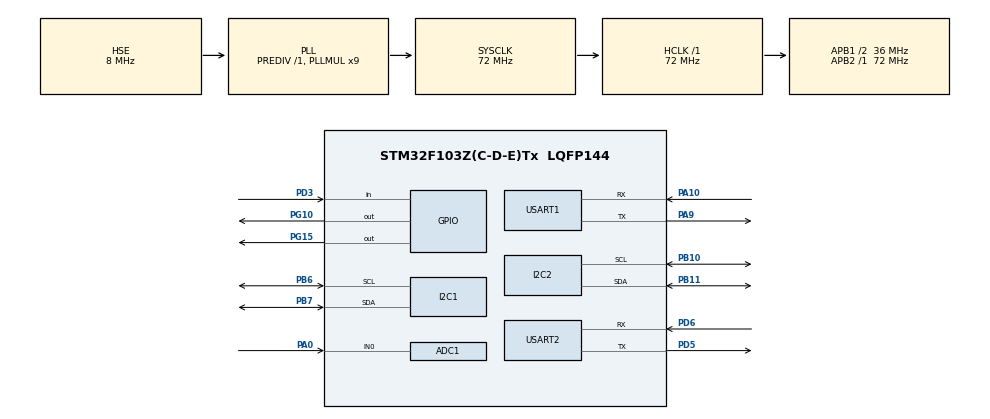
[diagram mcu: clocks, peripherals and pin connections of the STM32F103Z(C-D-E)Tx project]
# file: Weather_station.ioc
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ADC1.Channel-0\#ChannelRegularConversion=ADC_CHANNEL_0
ADC1.EnableInjectedConversion=ENABLE
ADC1.InjNumberOfConversion=1
ADC1.NbrOfConversion=1
ADC1.NbrOfConversionFlag=1
ADC1.Rank-0\#ChannelRegularConversion=1
ADC1.SamplingTime-0\#ChannelRegularConversion=ADC_SAMPLETIME_1CYCLE_5
ADC1.master=1
Mcu.Family=STM32F1
Mcu.Name=STM32F103Z(C-D-E)Tx
Mcu.Package=LQFP144
NVIC.PriorityGroup=NVIC_PRIORITYGROUP_4
NVIC.USART1_IRQn=true\:0\:0\:false\:false\:true\:true\:true\:true
OSC_IN.Mode=HSE-External-Oscillator
OSC_IN.Signal=RCC_OSC_IN
OSC_OUT.Mode=HSE-External-Oscillator
OSC_OUT.Signal=RCC_OSC_OUT
PA0-WKUP.Signal=ADCx_IN0
PA10.Mode=Asynchronous
PA10.Signal=USART1_RX
PA13.Mode=Serial_Wire
PA13.Signal=SYS_JTMS-SWDIO
PA14.Mode=Serial_Wire
PA14.Signal=SYS_JTCK-SWCLK
PA9.Mode=Asynchronous
PA9.Signal=USART1_TX
PB10.Mode=I2C
PB10.Signal=I2C2_SCL
PB11.Mode=I2C
PB11.Signal=I2C2_SDA
PB6.Mode=I2C
PB6.Signal=I2C1_SCL
PB7.Mode=I2C
PB7.Signal=I2C1_SDA
PC14-OSC32_IN.Mode=LSE-External-Oscillator
PC14-OSC32_IN.Signal=RCC_OSC32_IN
PC15-OSC32_OUT.Mode=LSE-External-Oscillator
PC15-OSC32_OUT.Signal=RCC_OSC32_OUT
PD3.Signal=GPIO_Input
PD5.Mode=Asynchronous
PD5.Signal=USART2_TX
PD6.Mode=Asynchronous
PD6.Signal=USART2_RX
PG10.GPIO_ModeDefaultOutputPP=GPIO_MODE_OUTPUT_PP
PG10.GPIO_PuPd=GPIO_PULLDOWN
PG10.PinState=GPIO_PIN_RESET
PG10.Signal=GPIO_Output
PG15.GPIO_PuPd=GPIO_PULLDOWN
PG15.Signal=GPIO_Output
ProjectManager.HeapSize=0x200
ProjectManager.StackSize=0x400
ProjectManager.TargetToolchain=Makefile
RCC.ADCPresc=RCC_ADCPCLK2_DIV6
RCC.AHBFreq_Value=72000000
RCC.APB1CLKDivider=RCC_HCLK_DIV2
RCC.APB1Freq_Value=36000000
RCC.APB1TimFreq_Value=72000000
RCC.APB2Freq_Value=72000000
RCC.APB2TimFreq_Value=72000000
RCC.HCLKFreq_Value=72000000
RCC.PLLMUL=RCC_PLL_MUL9
RCC.PLLSourceVirtual=RCC_PLLSOURCE_HSE
RCC.SYSCLKFreq_VALUE=72000000
RCC.SYSCLKSource=RCC_SYSCLKSOURCE_PLLCLK
RCC.USBFreq_Value=72000000
SH.ADCx_IN0.0=ADC1_IN0,IN0
TIM4.Period=20000-1
TIM4.Prescaler=7200-1
USART1.VirtualMode=VM_ASYNC
USART2.VirtualMode=VM_ASYNC
VP_TIM4_VS_ClockSourceINT.Mode=Internal
board=custom

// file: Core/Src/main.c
/* USER CODE BEGIN Header */
/**
  ******************************************************************************
  * @file           : main.c
  * @brief          : Main program body
  ******************************************************************************
  * @attention
  *
  * Copyright (c) 2026 STMicroelectronics.
  * All rights reserved.
  *
  * This software is licensed under terms that can be found in the LICENSE file
  * in the root directory of this software component.
  * If no LICENSE file comes with this software, it is provided AS-IS.
  *
  ******************************************************************************
  */
/* USER CODE END Header */
#include "main.h"
#include "adc.h"
#include "i2c.h"
#include "tim.h"
#include "usart.h"
#include "gpio.h"

/* USER CODE BEGIN Includes */
#include "app/app.h"
#include "test/test.h"
/* USER CODE END Includes */

void SystemClock_Config(void);

int main(void)
{

  /* MCU Configuration--------------------------------------------------------*/

  /* Reset of all peripherals, Initializes the Flash interface and the Systick. */
  HAL_Init();

  /* Configure the system clock */
  SystemClock_Config();

  /* Initialize all configured peripherals */
  MX_GPIO_Init();
  MX_USART1_UART_Init();
  MX_USART2_UART_Init();
  MX_ADC1_Init();
  MX_I2C1_Init();
  MX_I2C2_Init();
  MX_TIM4_Init();
  /* USER CODE BEGIN 2 */
  // app_init();
  test_hw_init();
  /* USER CODE END 2 */

  /* Infinite loop */
  while (1)
  {
    test_hw_loop();
  }
}

void SystemClock_Config(void)
{
  RCC_OscInitTypeDef RCC_OscInitStruct = {0};
  RCC_ClkInitTypeDef RCC_ClkInitStruct = {0};
  RCC_PeriphCLKInitTypeDef PeriphClkInit = {0};

  /** Initializes the RCC Oscillators according to the specified parameters
  * in the RCC_OscInitTypeDef structure.
  */
  RCC_OscInitStruct.OscillatorType = RCC_OSCILLATORTYPE_HSE;
  RCC_OscInitStruct.HSEState = RCC_HSE_ON;
  RCC_OscInitStruct.HSEPredivValue = RCC_HSE_PREDIV_DIV1;
  RCC_OscInitStruct.HSIState = RCC_HSI_ON;
  RCC_OscInitStruct.PLL.PLLState = RCC_PLL_ON;
  RCC_OscInitStruct.PLL.PLLSource = RCC_PLLSOURCE_HSE;
  RCC_OscInitStruct.PLL.PLLMUL = RCC_PLL_MUL9;
  if (HAL_RCC_OscConfig(&RCC_OscInitStruct) != HAL_OK)
  {
    Error_Handler();
  }

  /** Initializes the CPU, AHB and APB buses clocks
  */
  RCC_ClkInitStruct.ClockType = RCC_CLOCKTYPE_HCLK|RCC_CLOCKTYPE_SYSCLK
                              |RCC_CLOCKTYPE_PCLK1|RCC_CLOCKTYPE_PCLK2;
  RCC_ClkInitStruct.SYSCLKSource = RCC_SYSCLKSOURCE_PLLCLK;
  RCC_ClkInitStruct.AHBCLKDivider = RCC_SYSCLK_DIV1;
  RCC_ClkInitStruct.APB1CLKDivider = RCC_HCLK_DIV2;
  RCC_ClkInitStruct.APB2CLKDivider = RCC_HCLK_DIV1;

  if (HAL_RCC_ClockConfig(&RCC_ClkInitStruct, FLASH_LATENCY_2) != HAL_OK)
  {
    Error_Handler();
  }
  PeriphClkInit.PeriphClockSelection = RCC_PERIPHCLK_ADC;
  PeriphClkInit.AdcClockSelection = RCC_ADCPCLK2_DIV6;
  if (HAL_RCCEx_PeriphCLKConfig(&PeriphClkInit) != HAL_OK)
  {
    Error_Handler();
  }
}

void Error_Handler(void)
{
  __disable_irq();
  while (1)
  {
  }
}
